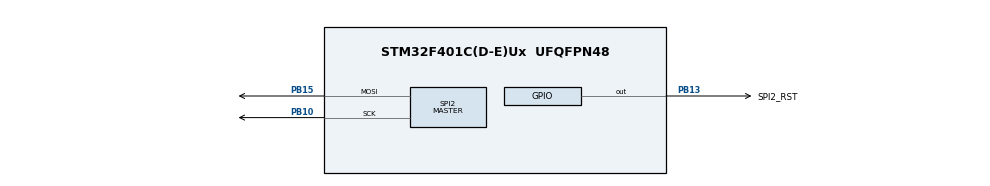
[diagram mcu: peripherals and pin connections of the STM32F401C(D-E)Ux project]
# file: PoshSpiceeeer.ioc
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Mcu.Family=STM32F4
Mcu.Name=STM32F401C(D-E)Ux
Mcu.Package=UFQFPN48
NVIC.PriorityGroup=NVIC_PRIORITYGROUP_4
PB10.Mode=TX_Only_Simplex_Unidirect_Master
PB10.Signal=SPI2_SCK
PB13.GPIO_Label=SPI2_RST
PB13.Signal=GPIO_Output
PB15.Mode=TX_Only_Simplex_Unidirect_Master
PB15.Signal=SPI2_MOSI
PH0\ -\ OSC_IN.Mode=HSE-External-Oscillator
PH0\ -\ OSC_IN.Signal=RCC_OSC_IN
PH1\ -\ OSC_OUT.Mode=HSE-External-Oscillator
PH1\ -\ OSC_OUT.Signal=RCC_OSC_OUT
ProjectManager.HeapSize=0x200
ProjectManager.StackSize=0x400
ProjectManager.TargetToolchain=Makefile
RCC.48MHZClocksFreq_Value=42000000
RCC.AHBFreq_Value=84000000
RCC.APB1CLKDivider=RCC_HCLK_DIV2
RCC.APB1Freq_Value=42000000
RCC.APB1TimFreq_Value=84000000
RCC.APB2Freq_Value=84000000
RCC.APB2TimFreq_Value=84000000
RCC.CortexFreq_Value=84000000
RCC.HCLKFreq_Value=84000000
RCC.HSE_VALUE=25000000
RCC.HSI_VALUE=16000000
RCC.LSE_VALUE=32768
RCC.PLLM=25
RCC.PLLN=168
RCC.PLLSourceVirtual=RCC_PLLSOURCE_HSE
RCC.SYSCLKFreq_VALUE=84000000
RCC.SYSCLKSource=RCC_SYSCLKSOURCE_PLLCLK
RCC.VCOOutputFreq_Value=168000000
SPI2.BaudRatePrescaler=SPI_BAUDRATEPRESCALER_64
SPI2.CLKPhase=SPI_PHASE_1EDGE
SPI2.CLKPolarity=SPI_POLARITY_LOW
SPI2.Direction=SPI_DIRECTION_2LINES
SPI2.FirstBit=SPI_FIRSTBIT_MSB
SPI2.Mode=SPI_MODE_MASTER
SPI2.VirtualType=VM_MASTER
board=custom

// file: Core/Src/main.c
/* USER CODE BEGIN Header */
/**
  ******************************************************************************
  * @file           : main.c
  * @brief          : Main program body
  ******************************************************************************
  * @attention
  *
  * Copyright (c) 2023 STMicroelectronics.
  * All rights reserved.
  *
  * This software is licensed under terms that can be found in the LICENSE file
  * in the root directory of this software component.
  * If no LICENSE file comes with this software, it is provided AS-IS.
  *
  ******************************************************************************
  */
/* USER CODE END Header */
#include "main.h"

/* USER CODE BEGIN Includes */
#include "app.h"

/* USER CODE END Includes */

void SystemClock_Config(void);
static void MX_GPIO_Init(void);
static void MX_SPI2_Init(void);

int main(void)
{

  /* MCU Configuration--------------------------------------------------------*/

  /* Reset of all peripherals, Initializes the Flash interface and the Systick. */
  LL_APB2_GRP1_EnableClock(LL_APB2_GRP1_PERIPH_SYSCFG);
  LL_APB1_GRP1_EnableClock(LL_APB1_GRP1_PERIPH_PWR);

  /* System interrupt init*/
  NVIC_SetPriorityGrouping(NVIC_PRIORITYGROUP_4);

  /* SysTick_IRQn interrupt configuration */
  NVIC_SetPriority(SysTick_IRQn, NVIC_EncodePriority(NVIC_GetPriorityGrouping(),15, 0));

  /* Configure the system clock */
  SystemClock_Config();

  /* Initialize all configured peripherals */
  MX_GPIO_Init();
  MX_SPI2_Init();
  /* USER CODE BEGIN 2 */
  LL_AHB1_GRP1_EnableClock(LL_AHB1_GRP1_PERIPH_GPIOA);
  App* app = app_alloc();
  app_run(app);
  /* USER CODE END 2 */

  /* Infinite loop */
  while (1)
  {

    /* USER CODE BEGIN 3 */
    app_free(app);
    break;
  }
  /* USER CODE END 3 */
}

void SystemClock_Config(void)
{
  LL_FLASH_SetLatency(LL_FLASH_LATENCY_2);
  while(LL_FLASH_GetLatency()!= LL_FLASH_LATENCY_2)
  {
  }
  LL_PWR_SetRegulVoltageScaling(LL_PWR_REGU_VOLTAGE_SCALE2);
  LL_RCC_HSE_Enable();

   /* Wait till HSE is ready */
  while(LL_RCC_HSE_IsReady() != 1)
  {

  }
  LL_RCC_PLL_ConfigDomain_SYS(LL_RCC_PLLSOURCE_HSE, LL_RCC_PLLM_DIV_25, 168, LL_RCC_PLLP_DIV_2);
  LL_RCC_PLL_Enable();

   /* Wait till PLL is ready */
  while(LL_RCC_PLL_IsReady() != 1)
  {

  }
  LL_RCC_SetAHBPrescaler(LL_RCC_SYSCLK_DIV_1);
  LL_RCC_SetAPB1Prescaler(LL_RCC_APB1_DIV_2);
  LL_RCC_SetAPB2Prescaler(LL_RCC_APB2_DIV_1);
  LL_RCC_SetSysClkSource(LL_RCC_SYS_CLKSOURCE_PLL);

   /* Wait till System clock is ready */
  while(LL_RCC_GetSysClkSource() != LL_RCC_SYS_CLKSOURCE_STATUS_PLL)
  {

  }
  LL_Init1msTick(84000000);
  LL_SetSystemCoreClock(84000000);
  LL_RCC_SetTIMPrescaler(LL_RCC_TIM_PRESCALER_TWICE);
}

static void MX_SPI2_Init(void)
{

  LL_SPI_InitTypeDef SPI_InitStruct = {0};

  LL_GPIO_InitTypeDef GPIO_InitStruct = {0};

  /* Peripheral clock enable */
  LL_APB1_GRP1_EnableClock(LL_APB1_GRP1_PERIPH_SPI2);

  LL_AHB1_GRP1_EnableClock(LL_AHB1_GRP1_PERIPH_GPIOB);
  /**SPI2 GPIO Configuration
  PB10   ------> SPI2_SCK
  PB15   ------> SPI2_MOSI
  */
  GPIO_InitStruct.Pin = LL_GPIO_PIN_10|LL_GPIO_PIN_15;
  GPIO_InitStruct.Mode = LL_GPIO_MODE_ALTERNATE;
  GPIO_InitStruct.Speed = LL_GPIO_SPEED_FREQ_VERY_HIGH;
  GPIO_InitStruct.OutputType = LL_GPIO_OUTPUT_PUSHPULL;
  GPIO_InitStruct.Pull = LL_GPIO_PULL_NO;
  GPIO_InitStruct.Alternate = LL_GPIO_AF_5;
  LL_GPIO_Init(GPIOB, &GPIO_InitStruct);

  /* SPI2 parameter configuration*/
  SPI_InitStruct.TransferDirection = LL_SPI_FULL_DUPLEX;
  SPI_InitStruct.Mode = LL_SPI_MODE_MASTER;
  SPI_InitStruct.DataWidth = LL_SPI_DATAWIDTH_8BIT;
  SPI_InitStruct.ClockPolarity = LL_SPI_POLARITY_LOW;
  SPI_InitStruct.ClockPhase = LL_SPI_PHASE_1EDGE;
  SPI_InitStruct.NSS = LL_SPI_NSS_SOFT;
  SPI_InitStruct.BaudRate = LL_SPI_BAUDRATEPRESCALER_DIV64;
  SPI_InitStruct.BitOrder = LL_SPI_MSB_FIRST;
  SPI_InitStruct.CRCCalculation = LL_SPI_CRCCALCULATION_DISABLE;
  SPI_InitStruct.CRCPoly = 10;
  LL_SPI_Init(SPI2, &SPI_InitStruct);
  LL_SPI_SetStandard(SPI2, LL_SPI_PROTOCOL_MOTOROLA);

}

static void MX_GPIO_Init(void)
{
  LL_GPIO_InitTypeDef GPIO_InitStruct = {0};

  /* GPIO Ports Clock Enable */
  LL_AHB1_GRP1_EnableClock(LL_AHB1_GRP1_PERIPH_GPIOH);
  LL_AHB1_GRP1_EnableClock(LL_AHB1_GRP1_PERIPH_GPIOB);

  /**/
  LL_GPIO_ResetOutputPin(SPI2_RST_GPIO_Port, SPI2_RST_Pin);

  /**/
  GPIO_InitStruct.Pin = SPI2_RST_Pin;
  GPIO_InitStruct.Mode = LL_GPIO_MODE_OUTPUT;
  GPIO_InitStruct.Speed = LL_GPIO_SPEED_FREQ_LOW;
  GPIO_InitStruct.OutputType = LL_GPIO_OUTPUT_PUSHPULL;
  GPIO_InitStruct.Pull = LL_GPIO_PULL_NO;
  LL_GPIO_Init(SPI2_RST_GPIO_Port, &GPIO_InitStruct);

}

void Error_Handler(void)
{
  __disable_irq();
  while (1)
  {
  }
}
